# K1921VG7T register map
Vendor: NIIET; Series: K1921VKx; File version: 1.0
CPU: CM4 r0p1, Endian.LITTLE endian, MPU, FPU
Registers are 32-bit, read-write, reset 0x0 unless marked. A register's access mark holds for its fields unless they carry their own. Offsets are from the block's base; [hi:lo] are bit positions; lines under a group give offsets from that group; {n}, {i} and the like mark numbered series.

## GPIOA — GPIO control registers
Base 0x40000000
Same registers: GPIOB 0x40001000
0x00 DATA ro — Data Input register
  [15:0] VAL — Data input
0x04 DATAOUT — Data output register
  [15:0] VAL — Data output
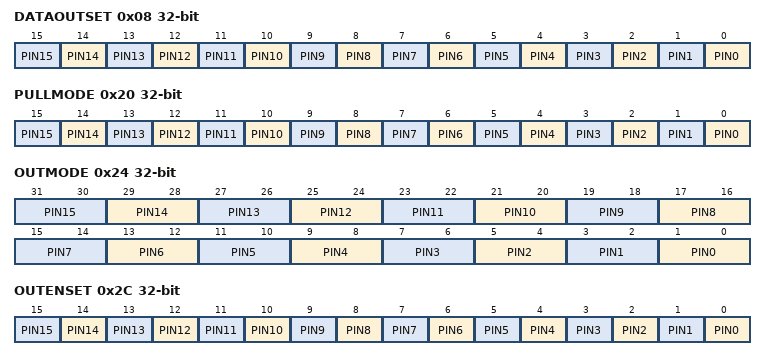
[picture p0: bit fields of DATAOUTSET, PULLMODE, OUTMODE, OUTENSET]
0x08 DATAOUTSET wo — Data output set bits register
  [n] PIN{n} (n=0..15) — Data output set bit {n}
0x0C DATAOUTCLR wo — Data output clear bits register
  [15:0] VAL — Data output clear
0x10 DATAOUTTGL wo — Data output toggle bits register
  [15:0] VAL — Data output toggle
0x20 PULLMODE — Select pull mode register
  [all] fields
    0=Disable (Pull disabled); 1=PU (Pull-up)
  [n] PIN{n} (n=0..15) — Select pull mode for pin {n}
0x24 OUTMODE — Select output mode register
  [all] fields
    0=PP (Push-pull output); 1=OD (Open drain output); 2=OS (Open source output)
  [2n+1:2n] PIN{n} (n=0..15) — Select output mode for pin {n}
0x2C OUTENSET — Output enable register
  [n] PIN{n} (n=0..15) — Output enable for pin {n}
0x30 OUTENCLR wo — Output disable register
  [15:0] VAL — Output disable
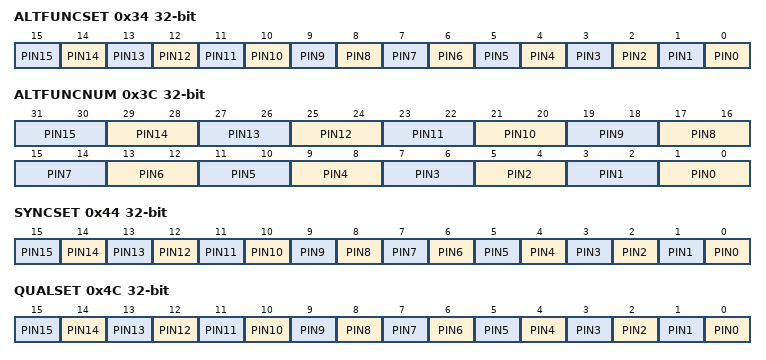
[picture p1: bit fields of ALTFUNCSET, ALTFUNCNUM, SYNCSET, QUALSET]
0x34 ALTFUNCSET — Alternative function enable register
  [n] PIN{n} (n=0..15) — Alternative function enable for pin {n}
0x38 ALTFUNCCLR wo — Alternative function disable register
  [15:0] VAL — Alternative function disable
0x3C ALTFUNCNUM — Alternative function number register
  [all] fields
    0=Disable (Altfunc disabled); 1=AF1 (Altfunc 1 enable); 2=AF2 (Altfunc 2 enable); 3=AF3 (Altfunc 3 enable)
  [2n+1:2n] PIN{n} (n=0..15) — Select altfunc number for pin {n}
0x44 SYNCSET — Additional double flip-flop syncronization enable register
  [n] PIN{n} (n=0..15) — Additional double flip-flop syncronization buffer enable for pin {n}
0x48 SYNCCLR wo — Additional double flip-flop syncronization disable register
  [15:0] VAL — Additional double flip-flop syncronization disable
0x4C QUALSET — Qualifier enable register
  [n] PIN{n} (n=0..15) — Qualifier enable for pin {n}
0x50 QUALCLR wo — Qualifier disable register
  [15:0] VAL — Qualifier disable
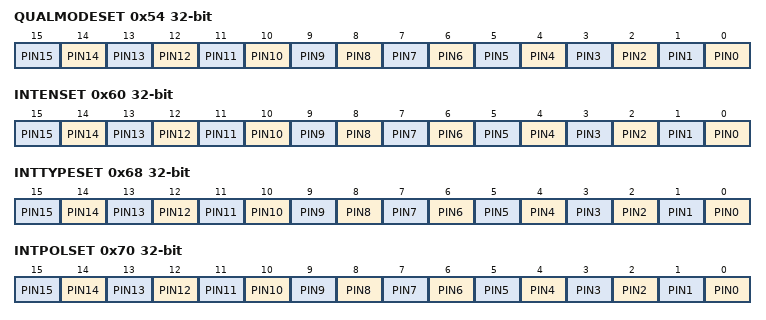
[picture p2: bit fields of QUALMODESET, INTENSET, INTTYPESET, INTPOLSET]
0x54 QUALMODESET — Qualifier mode set register
  [n] PIN{n} (n=0..15) — Qualifier mode set for pin {n}
0x58 QUALMODECLR wo — Qualifier mode clear register
  [15:0] VAL — Qualifier mode clear
0x5C QUALSAMPLE — Qualifier sample period register
  [7:0] VAL — Qualifier sample period
0x60 INTENSET — Interrupt enable register
  [n] PIN{n} (n=0..15) — Interrupt enable for pin {n}
0x64 INTENCLR wo — Interrupt disable register
  [15:0] VAL — Interrupt disable
0x68 INTTYPESET — Interrupt type set register
  [n] PIN{n} (n=0..15) — Interrupt type set for pin {n}
0x6C INTTYPECLR wo — Interrupt type clear register
  [15:0] VAL — Interrupt type clear
0x70 INTPOLSET — Interrupt polarity set register
  [n] PIN{n} (n=0..15) — Interrupt polarity set for pin {n}
0x74 INTPOLCLR wo — Interrupt polarity clear register
  [15:0] VAL — Interrupt polarity clear
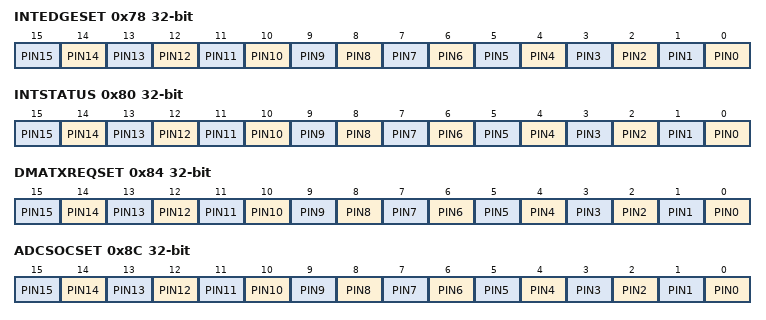
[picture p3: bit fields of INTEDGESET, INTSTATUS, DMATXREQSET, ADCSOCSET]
0x78 INTEDGESET — Interrupt every edge set register
  [n] PIN{n} (n=0..15) — Interrupt every edge set for pin {n}
0x7C INTEDGECLR wo — Interrupt every edge clear register
  [15:0] VAL — Interrupt every edge clear
0x80 INTSTATUS — Interrupt status
  [n] PIN{n} (n=0..15) — Interrupt status of pin {n}
0x84 DMATXREQSET — DMA TX request enable register
  [n] PIN{n} (n=0..15) — DMA request enable for pin {n}
0x88 DMATXREQCLR wo — DMA TX request disable register
  [15:0] VAL — DMA request disable
0x8C ADCSOCSET — ADC Start Of Conversion enable register
  [n] PIN{n} (n=0..15) — ADC SOC enable for pin {n}
0x90 ADCSOCCLR wo — ADC Start Of Conversion disable register
  [15:0] VAL — ADC SOC disable
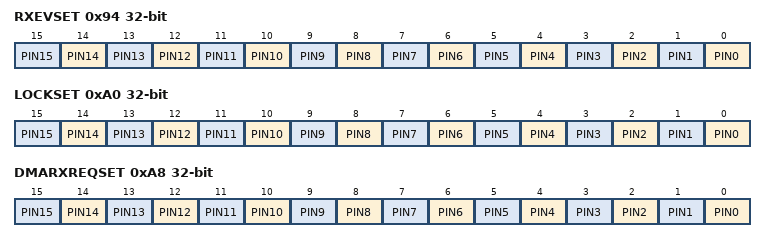
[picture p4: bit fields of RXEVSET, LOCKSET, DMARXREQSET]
0x94 RXEVSET — Core RXEV request enable register
  [n] PIN{n} (n=0..15) — RXEV enable for pin {n}
0x98 RXEVCLR wo — Core RXEV request disable register
  [15:0] VAL — RXEV disable
0x9C LOCKKEY wo — Key register to unlock LOCKSET/LOCKCLR registers for write (KEY=0xADEADBEE)
  [31:0] VAL — Key to unlock LOCKSET/LOCKCLR registers for write (KEY=0xADEADBEE)
    0xEEEEEEEE=LOCK (Example value to disable write to LOCKSET/LOCKCLR); 0=LOCK_0 (Example value to disable write to LOCKSET/LOCKCLR); 1=LOCK_1 (Example value to disable write to LOCKSET/LOCKCLR); 0xADEADBEE=UNLOCK (Key to unlock write to LOCKSET/LOCKCLR)
0x9C LOCKSTAT ro (alternate view of LOCKKEY) — Write LOCKSET/LOCKCLR enable status register
  [0] WREN — Write LOCKSET/LOCKCLR enable status
0xA0 LOCKSET — Lock pins configuration enable register
  [n] PIN{n} (n=0..15) — Lock configuration enable for pin {n}
0xA4 LOCKCLR wo — Lock pins configuration disable register
  [15:0] VAL — Lock configuration disable
0xA8 DMARXREQSET — DMA RX request enable register
  [n] PIN{n} (n=0..15) — DMA request enable for pin {n}
0xAC DMARXREQCLR wo — DMA RX request disable register
  [15:0] VAL — DMA request disable
{0x400+4i} MASKLB[{i}] (i=0..255) group
  0x00 ? — Mask register low byte of port
    [7:0] VAL — Mask low byte
{0x800+4i} MASKHB[{i}] (i=0..255) group
  0x00 ? — Mask register High byte of port
    [15:8] VAL — Mask high byte
